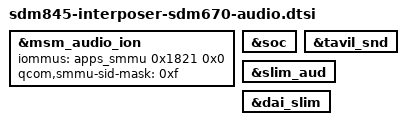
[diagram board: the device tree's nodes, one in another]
/* Copyright (c) 2017, The Linux Foundation. All rights reserved.
 *
 * This program is free software; you can redistribute it and/or modify
 * it under the terms of the GNU General Public License version 2 and
 * only version 2 as published by the Free Software Foundation.
 *
 * This program is distributed in the hope that it will be useful,
 * but WITHOUT ANY WARRANTY; without even the implied warranty of
 * MERCHANTABILITY or FITNESS FOR A PARTICULAR PURPOSE.  See the
 * GNU General Public License for more details.
 */


&msm_audio_ion {
	iommus = <&apps_smmu 0x1821 0x0>;
	qcom,smmu-sid-mask = /bits/ 64 <0xf>;
};

&soc {
	/delete-node/sound;
};

&tavil_snd {
	status = "okay";
};

&slim_aud {
	status = "okay";
};

&dai_slim {
	status = "okay";
};
